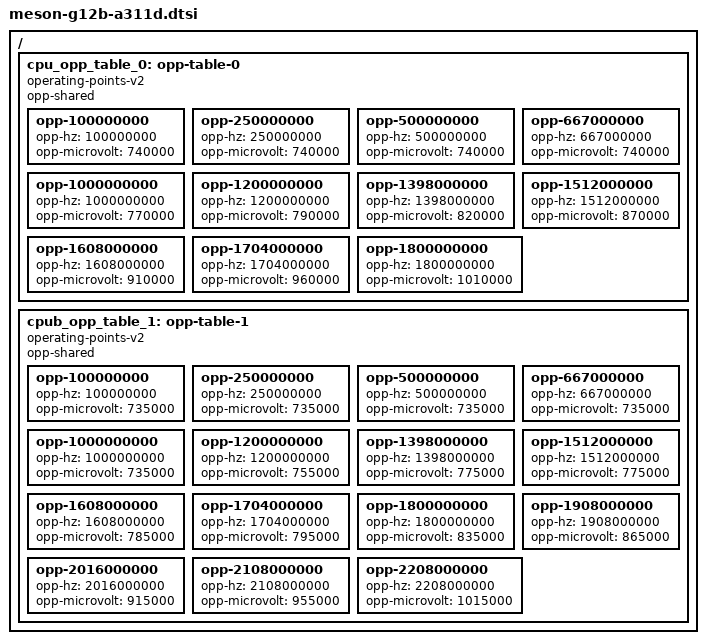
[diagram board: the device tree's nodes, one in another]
// SPDX-License-Identifier: (GPL-2.0+ OR MIT)
/*
 * Copyright (c) 2019 BayLibre, SAS
 * Author: Neil Armstrong <narmstrong@baylibre.com>
 */

#include "meson-g12b.dtsi"

/ {
	cpu_opp_table_0: opp-table-0 {
		compatible = "operating-points-v2";
		opp-shared;

		opp-100000000 {
			opp-hz = /bits/ 64 <100000000>;
			opp-microvolt = <740000>;
		};

		opp-250000000 {
			opp-hz = /bits/ 64 <250000000>;
			opp-microvolt = <740000>;
		};

		opp-500000000 {
			opp-hz = /bits/ 64 <500000000>;
			opp-microvolt = <740000>;
		};

		opp-667000000 {
			opp-hz = /bits/ 64 <667000000>;
			opp-microvolt = <740000>;
		};

		opp-1000000000 {
			opp-hz = /bits/ 64 <1000000000>;
			opp-microvolt = <770000>;
		};

		opp-1200000000 {
			opp-hz = /bits/ 64 <1200000000>;
			opp-microvolt = <790000>;
		};

		opp-1398000000 {
			opp-hz = /bits/ 64 <1398000000>;
			opp-microvolt = <820000>;
		};

		opp-1512000000 {
			opp-hz = /bits/ 64 <1512000000>;
			opp-microvolt = <870000>;
		};

		opp-1608000000 {
			opp-hz = /bits/ 64 <1608000000>;
			opp-microvolt = <910000>;
		};

		opp-1704000000 {
			opp-hz = /bits/ 64 <1704000000>;
			opp-microvolt = <960000>;
		};

		opp-1800000000 {
			opp-hz = /bits/ 64 <1800000000>;
			opp-microvolt = <1010000>;
		};
	};

	cpub_opp_table_1: opp-table-1 {
		compatible = "operating-points-v2";
		opp-shared;

		opp-100000000 {
			opp-hz = /bits/ 64 <100000000>;
			opp-microvolt = <735000>;
		};

		opp-250000000 {
			opp-hz = /bits/ 64 <250000000>;
			opp-microvolt = <735000>;
		};

		opp-500000000 {
			opp-hz = /bits/ 64 <500000000>;
			opp-microvolt = <735000>;
		};

		opp-667000000 {
			opp-hz = /bits/ 64 <667000000>;
			opp-microvolt = <735000>;
		};

		opp-1000000000 {
			opp-hz = /bits/ 64 <1000000000>;
			opp-microvolt = <735000>;
		};

		opp-1200000000 {
			opp-hz = /bits/ 64 <1200000000>;
			opp-microvolt = <755000>;
		};

		opp-1398000000 {
			opp-hz = /bits/ 64 <1398000000>;
			opp-microvolt = <775000>;
		};

		opp-1512000000 {
			opp-hz = /bits/ 64 <1512000000>;
			opp-microvolt = <775000>;
		};

		opp-1608000000 {
			opp-hz = /bits/ 64 <1608000000>;
			opp-microvolt = <785000>;
		};

		opp-1704000000 {
			opp-hz = /bits/ 64 <1704000000>;
			opp-microvolt = <795000>;
		};

		opp-1800000000 {
			opp-hz = /bits/ 64 <1800000000>;
			opp-microvolt = <835000>;
		};

                opp-1908000000 {
                        opp-hz = /bits/ 64 <1908000000>;
                        opp-microvolt = <865000>;
                };

                opp-2016000000 {
                        opp-hz = /bits/ 64 <2016000000>;
                        opp-microvolt = <915000>;
                };

                opp-2108000000 {
                        opp-hz = /bits/ 64 <2108000000>;
                        opp-microvolt = <955000>;
                };

                opp-2208000000 {
                        opp-hz = /bits/ 64 <2208000000>;
                        opp-microvolt = <1015000>;
                };
	};
};
